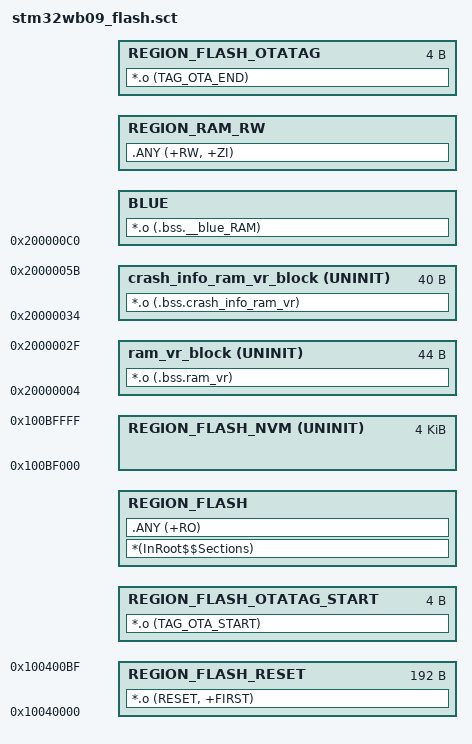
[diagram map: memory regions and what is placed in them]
#!armclang -E --target=arm-arm-none-eabi -mcpu=cortex-m0plus -xc
/*******************************************************************************
* STM32WB09 generic linker file for KEIL
* Main linker variables to control it are:
*
* MEMORY_FLASH_APP_SIZE: define the size of the application in case not all the flash is needed.
* Default value is: 508KB when no OTA firmware upgrade is supported
*
* MEMORY_FLASH_APP_OFFSET: define the offset of the application.
* Default value is: 0 offset
*
* MEMORY_RAM_APP_OFFSET: define the offset in RAM from which variables can be
* allocated.
* 
*******************************************************************************/

/*******************************************************************************
* Memory Definitions
*******************************************************************************/
/*
STM32WB09 memory map
+-----------------------+ 0x2000FFFF
|  RAM (64K)            |
+-----------------------+ 0x20000000
|                       |
|                       |
+-----------------------+ 0x100BFFFF
|                       |
|  FLASH (512K)         |
+-----------------------+ 0x10040000
|                       |
+-----------------------| 0x100017FF
|   ROM (6K)            |
+-----------------------+ 0x10000000
*/

#define _MEMORY_RAM_BEGIN_    0x20000000
#define _MEMORY_RAM_SIZE_     0x10000         /* 64KB  */
#define _MEMORY_RAM_END_      0x2000FFFF

#define _MEMORY_FLASH_BEGIN_  0x10040000  
#define _MEMORY_FLASH_SIZE_   0x80000          /* 512KB */ 
#define _MEMORY_FLASH_END_    0x100BFFFF  

#define _MEMORY_ROM_BEGIN_    0x10000000    
#define _MEMORY_ROM_SIZE_     0x1800           /* 6KB */ 
#define _MEMORY_ROM_END_      0x100017FF  


/* Reserved for BTLE stack non volatile memory */
#define FLASH_NVM_DATASIZE     (4*1024)

#ifndef MEMORY_FLASH_APP_OFFSET
#define MEMORY_FLASH_APP_OFFSET  (0)
#endif

#ifndef MEMORY_FLASH_APP_SIZE
#define MEMORY_FLASH_APP_SIZE  (_MEMORY_FLASH_SIZE_ - FLASH_NVM_DATASIZE - MEMORY_FLASH_APP_OFFSET)
#endif

LR_IROM1 (_MEMORY_FLASH_BEGIN_+MEMORY_FLASH_APP_OFFSET) (MEMORY_FLASH_APP_SIZE)  {    ; load region size_region
  
  REGION_FLASH_RESET (_MEMORY_FLASH_BEGIN_ + MEMORY_FLASH_APP_OFFSET) (0xC0)  { ; load address = execution address
   *.o (RESET, +FIRST)
  }
  
  REGION_FLASH_OTATAG_START +0 (0x04)  {
   *.o (TAG_OTA_START)
  }
  
  REGION_FLASH +0 {
   *(InRoot$$Sections)
   .ANY (+RO)
  }
  REGION_FLASH_NVM (_MEMORY_FLASH_END_- FLASH_NVM_DATASIZE + 1) UNINIT FLASH_NVM_DATASIZE  {
  }
  ram_vr_block 0x20000004 UNINIT 0x2C {
   *.o (.bss.ram_vr)
  }
  crash_info_ram_vr_block 0x20000034 UNINIT 40 {  
  *.o (.bss.crash_info_ram_vr)
  }
  BLUE 0x200000C0 {
  *.o (.bss.__blue_RAM)
  }
  
#ifndef MEMORY_RAM_APP_OFFSET
  REGION_RAM_RW +0  {  ; RW data
   .ANY (+RW, +ZI)
  }
#else
  REGION_RAM_RW (_MEMORY_RAM_BEGIN_ + MEMORY_RAM_APP_OFFSET) {  ; RW data
   .ANY (+RW, +ZI)
  }
#endif

}

LR_IROM2 +0 4  {

  REGION_FLASH_OTATAG +0 4 {
   *.o (TAG_OTA_END)
  }

}

ScatterAssert( ImageLimit(REGION_RAM_RW) <= _MEMORY_RAM_END_ + 1 )

ScatterAssert( LoadLimit(LR_IROM2) <= (_MEMORY_FLASH_BEGIN_ + MEMORY_FLASH_APP_OFFSET + MEMORY_FLASH_APP_SIZE) )
